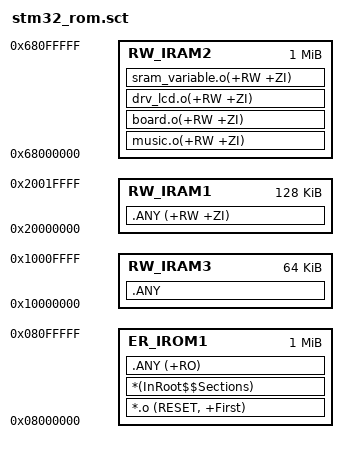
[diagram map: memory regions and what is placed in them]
; *************************************************************
; *** Scatter-Loading Description File generated by uVision ***
; *************************************************************

LR_IROM1 0x08000000 0x00100000  {    ; load region size_region
  ER_IROM1 0x08000000 0x00100000  {  ; load address = execution address
   *.o (RESET, +First)
   *(InRoot$$Sections)
   .ANY (+RO)
  }
  RW_IRAM1 0x20000000 0x00020000  {  ; RW data
   .ANY (+RW +ZI)
  }
  RW_IRAM2 0x68000000 0x00100000  {  ; RW data
   music.o(+RW +ZI)
   board.o(+RW +ZI)
   drv_lcd.o(+RW +ZI)
   sram_variable.o(+RW +ZI)
  }
  RW_IRAM3 0x10000000 0x00010000  {  ; RW data
   .ANY
  }
}

